# PIC32MK1024MCM064 register map
Vendor: Microchip
Registers are 32-bit, read-write, reset 0x0 unless marked. A register's access mark holds for its fields unless they carry their own. Addresses are absolute, and some are shared; only a register's first bit layout is shown; [hi:lo] are bit positions; {n}, {i} and the like mark numbered series.

## PORTD
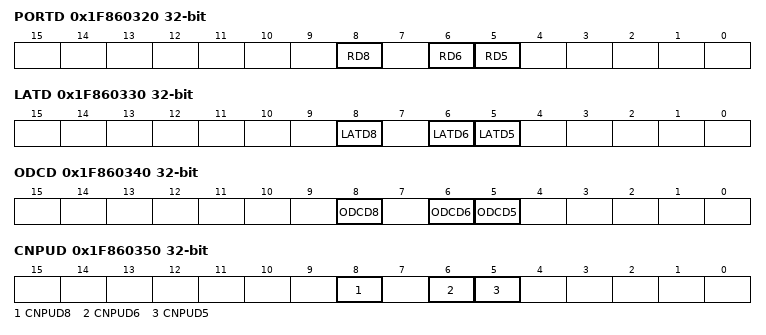
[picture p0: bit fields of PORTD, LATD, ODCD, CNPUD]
0x1F860320 PORTD reset not defined — (power-on value -----------------------x-xx-----)
  [8] RD8, [6] RD6, [5] RD5
0x1F860330 LATD reset not defined — (power-on value -----------------------x-xx-----)
  [8] LATD8, [6] LATD6, [5] LATD5
0x1F860340 ODCD
  [8] ODCD8, [6] ODCD6, [5] ODCD5
0x1F860350 CNPUD
  [8] CNPUD8, [6] CNPUD6, [5] CNPUD5
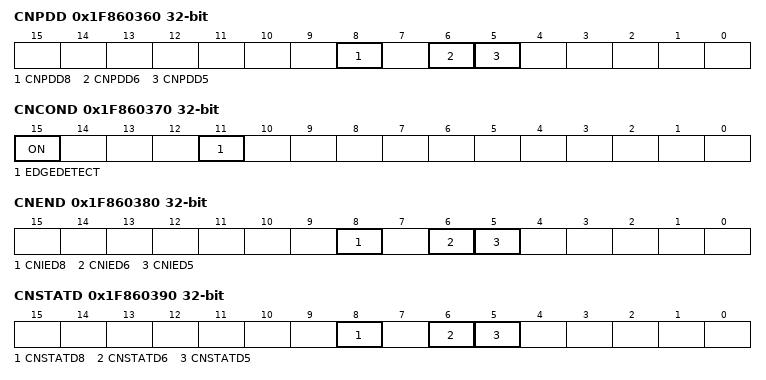
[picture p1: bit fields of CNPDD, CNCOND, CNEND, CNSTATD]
0x1F860360 CNPDD
  [8] CNPDD8, [6] CNPDD6, [5] CNPDD5
0x1F860370 CNCOND
  [15] ON, [11] EDGEDETECT
0x1F860380 CNEND
  [8] CNIED8, [6] CNIED6, [5] CNIED5
0x1F860390 CNSTATD
  [8] CNSTATD8, [6] CNSTATD6, [5] CNSTATD5
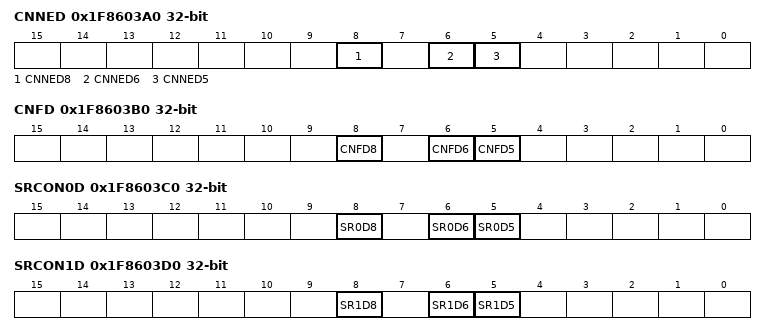
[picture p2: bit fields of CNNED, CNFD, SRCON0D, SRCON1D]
0x1F8603A0 CNNED
  [8] CNNED8, [6] CNNED6, [5] CNNED5
0x1F8603B0 CNFD
  [8] CNFD8, [6] CNFD6, [5] CNFD5
0x1F8603C0 SRCON0D
  [8] SR0D8, [6] SR0D6, [5] SR0D5
0x1F8603D0 SRCON1D
  [8] SR1D8, [6] SR1D6, [5] SR1D5

## PORTE
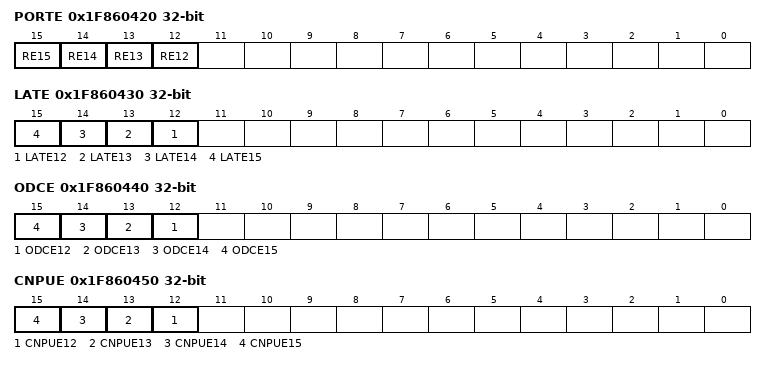
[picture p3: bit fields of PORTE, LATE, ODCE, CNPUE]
0x1F860420 PORTE reset not defined — (power-on value ----------------xxxx------------)
  [n] RE{n} (n=12..15)
0x1F860430 LATE reset not defined — (power-on value ----------------xxxx------------)
  [n] LATE{n} (n=12..15)
0x1F860440 ODCE
  [n] ODCE{n} (n=12..15)
0x1F860450 CNPUE
  [n] CNPUE{n} (n=12..15)
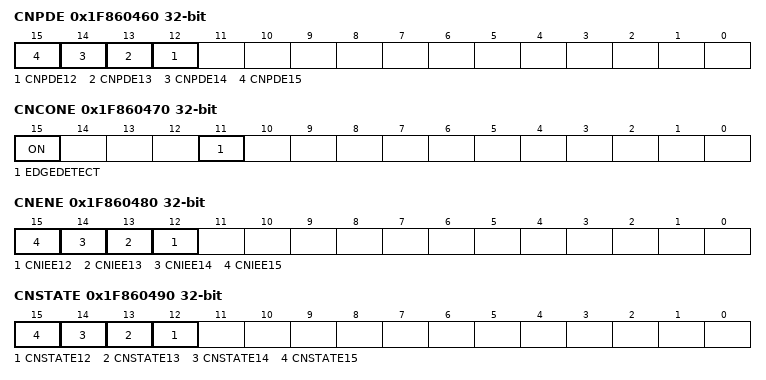
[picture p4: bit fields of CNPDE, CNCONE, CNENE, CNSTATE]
0x1F860460 CNPDE
  [n] CNPDE{n} (n=12..15)
0x1F860470 CNCONE
  [15] ON, [11] EDGEDETECT
0x1F860480 CNENE
  [n] CNIEE{n} (n=12..15)
0x1F860490 CNSTATE
  [n] CNSTATE{n} (n=12..15)
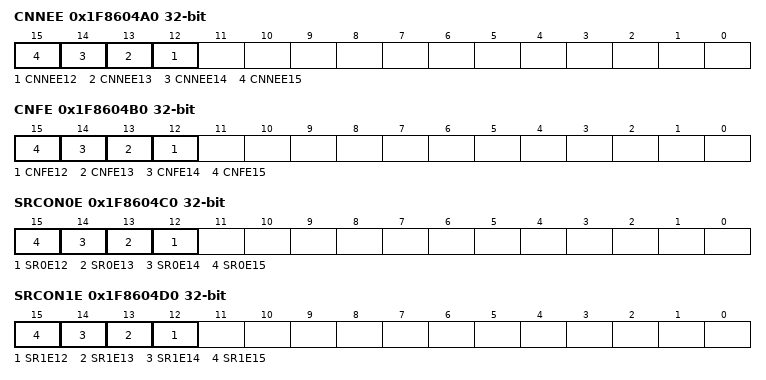
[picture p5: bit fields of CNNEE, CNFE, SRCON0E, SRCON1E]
0x1F8604A0 CNNEE
  [n] CNNEE{n} (n=12..15)
0x1F8604B0 CNFE
  [n] CNFE{n} (n=12..15)
0x1F8604C0 SRCON0E
  [n] SR0E{n} (n=12..15)
0x1F8604D0 SRCON1E
  [n] SR1E{n} (n=12..15)

## PORTF
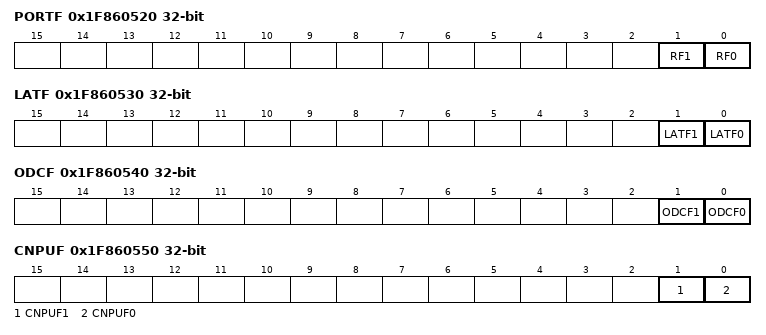
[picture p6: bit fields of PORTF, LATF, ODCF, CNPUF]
0x1F860520 PORTF reset not defined — (power-on value ------------------------------xx)
  [1] RF1, [0] RF0
0x1F860530 LATF reset not defined — (power-on value ------------------------------xx)
  [1] LATF1, [0] LATF0
0x1F860540 ODCF
  [1] ODCF1, [0] ODCF0
0x1F860550 CNPUF
  [1] CNPUF1, [0] CNPUF0
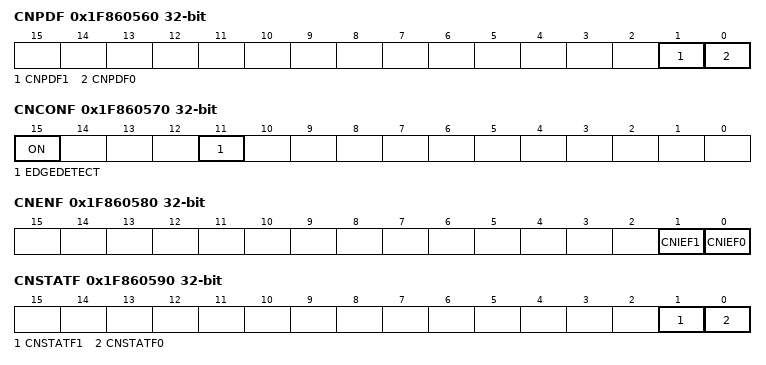
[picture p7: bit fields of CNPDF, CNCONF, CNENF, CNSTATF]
0x1F860560 CNPDF
  [1] CNPDF1, [0] CNPDF0
0x1F860570 CNCONF
  [15] ON, [11] EDGEDETECT
0x1F860580 CNENF
  [1] CNIEF1, [0] CNIEF0
0x1F860590 CNSTATF
  [1] CNSTATF1, [0] CNSTATF0
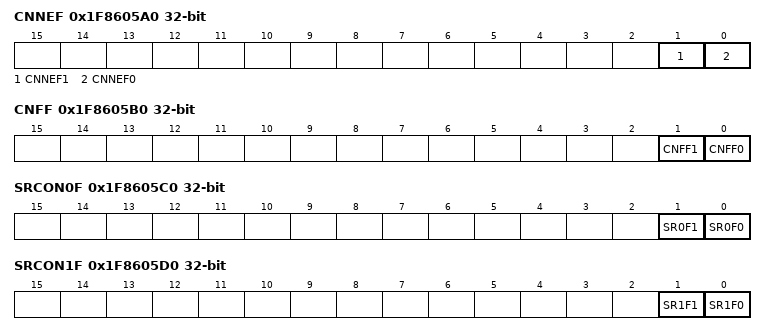
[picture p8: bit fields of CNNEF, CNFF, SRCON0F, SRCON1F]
0x1F8605A0 CNNEF
  [1] CNNEF1, [0] CNNEF0
0x1F8605B0 CNFF
  [1] CNFF1, [0] CNFF0
0x1F8605C0 SRCON0F
  [1] SR0F1, [0] SR0F0
0x1F8605D0 SRCON1F
  [1] SR1F1, [0] SR1F0

## PORTG
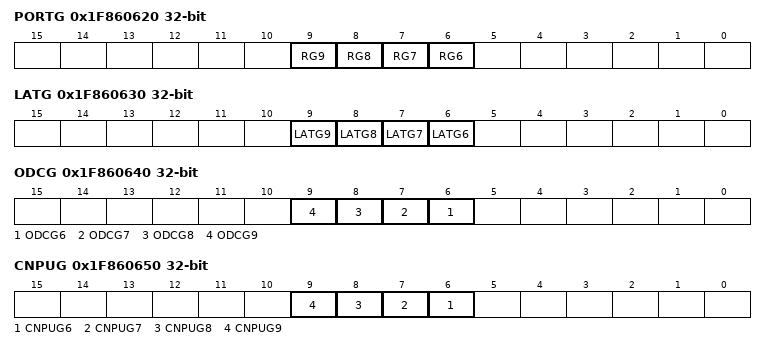
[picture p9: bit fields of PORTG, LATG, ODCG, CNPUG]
0x1F860620 PORTG reset not defined — (power-on value ----------------------xxxx------)
  [n] RG{n} (n=6..9)
0x1F860630 LATG reset not defined — (power-on value ----------------------xxxx------)
  [n] LATG{n} (n=6..9)
0x1F860640 ODCG
  [n] ODCG{n} (n=6..9)
0x1F860650 CNPUG
  [n] CNPUG{n} (n=6..9)
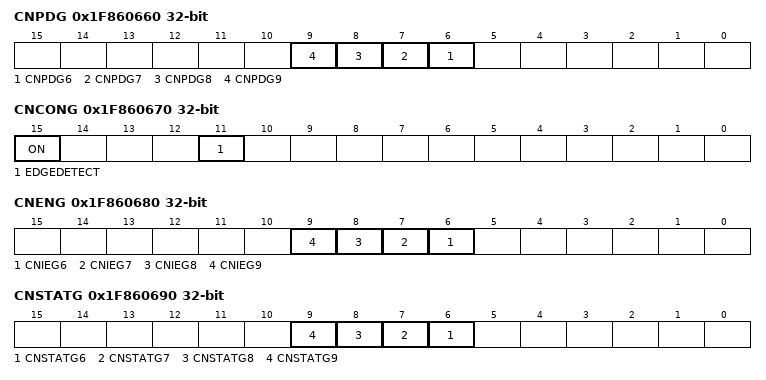
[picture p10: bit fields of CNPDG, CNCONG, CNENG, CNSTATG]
0x1F860660 CNPDG
  [n] CNPDG{n} (n=6..9)
0x1F860670 CNCONG
  [15] ON, [11] EDGEDETECT
0x1F860680 CNENG
  [n] CNIEG{n} (n=6..9)
0x1F860690 CNSTATG
  [n] CNSTATG{n} (n=6..9)
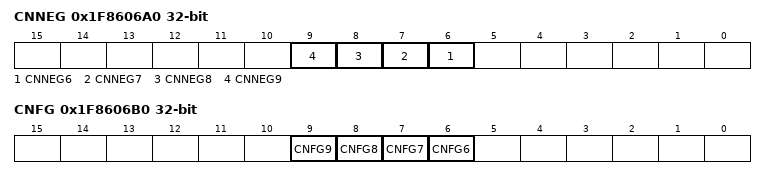
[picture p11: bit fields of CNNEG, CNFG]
0x1F8606A0 CNNEG
  [n] CNNEG{n} (n=6..9)
0x1F8606B0 CNFG
  [n] CNFG{n} (n=6..9)

## ADCHS
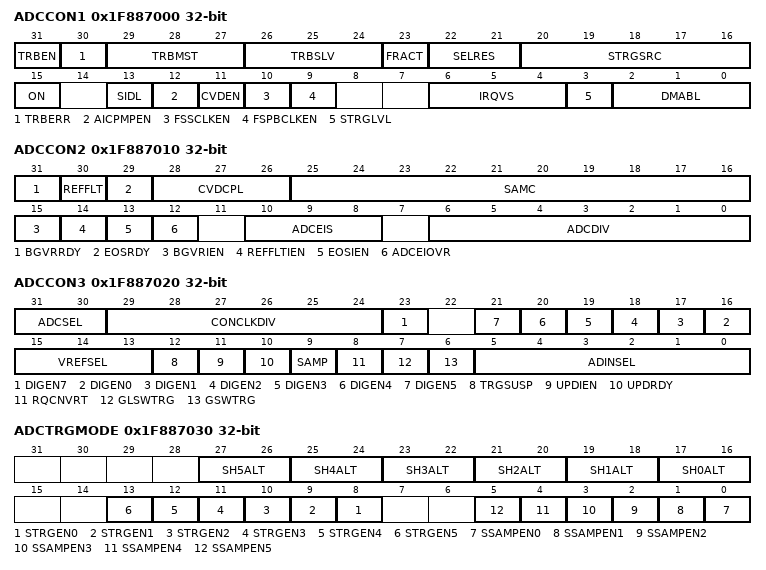
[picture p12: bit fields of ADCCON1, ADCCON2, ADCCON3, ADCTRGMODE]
0x1F887000 ADCCON1 reset not defined — (power-on value 00000110000000000-00000--0000xxx)
  [31] TRBEN, [30] TRBERR ro, [29:27] TRBMST, [26:24] TRBSLV, [23] FRACT, [22:21] SELRES, [20:16] STRGSRC, [15] ON, [13] SIDL, [12] AICPMPEN, [11] CVDEN, [10] FSSCLKEN, [9] FSPBCLKEN, [6:4] IRQVS, [3] STRGLVL, [2:0] DMABL
0x1F887010 ADCCON2
  [31] BGVRRDY ro, [30] REFFLT ro, [29] EOSRDY ro, [28:26] CVDCPL, [25:16] SAMC, [15] BGVRIEN, [14] REFFLTIEN, [13] EOSIEN, [12] ADCEIOVR, [10:8] ADCEIS, [6:0] ADCDIV
0x1F887020 ADCCON3
  [31:30] ADCSEL, [29:24] CONCLKDIV, [23] DIGEN7 ro, [n+16] DIGEN{n} ro (n=0..5), [15:13] VREFSEL, [12] TRGSUSP, [11] UPDIEN, [10] UPDRDY, [9] SAMP, [8] RQCNVRT, [7] GLSWTRG, [6] GSWTRG, [5:0] ADINSEL
0x1F887030 ADCTRGMODE
  [2n+17:2n+16] SH{n}ALT (n=0..5), [n+8] STRGEN{n} (n=0..5), [n] SSAMPEN{n} (n=0..5)
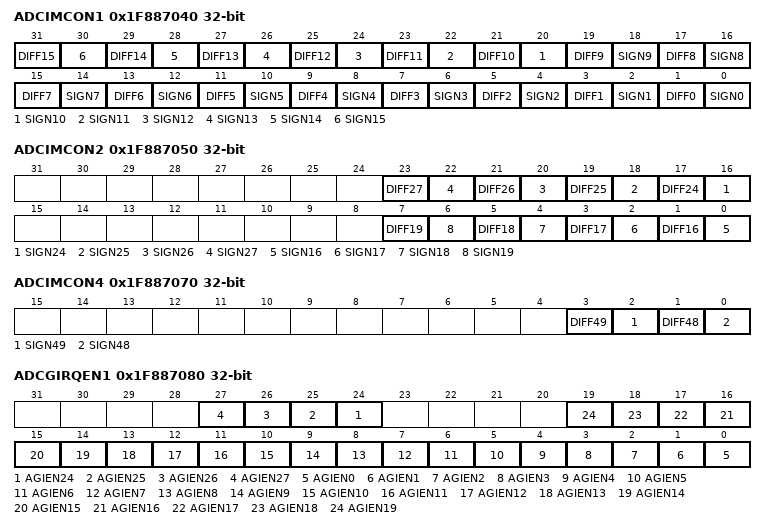
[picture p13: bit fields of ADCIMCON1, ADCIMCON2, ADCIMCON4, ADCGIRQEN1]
0x1F887040 ADCIMCON1
  [2n+1] DIFF{n} (n=0..15), [2n] SIGN{n} (n=0..15)
0x1F887050 ADCIMCON2
  [2n-31] DIFF{n} (n=24..27), [2n-32] SIGN{n} (n=24..27), [2n-31] DIFF{n} (n=16..19), [2n-32] SIGN{n} (n=16..19)
0x1F887060 ADCIMCON3 access not given reset not defined
0x1F887070 ADCIMCON4
  [3] DIFF49, [2] SIGN49, [1] DIFF48, [0] SIGN48
0x1F887080 ADCGIRQEN1
  [n] AGIEN{n} (n=24..27), [n] AGIEN{n} (n=0..19)
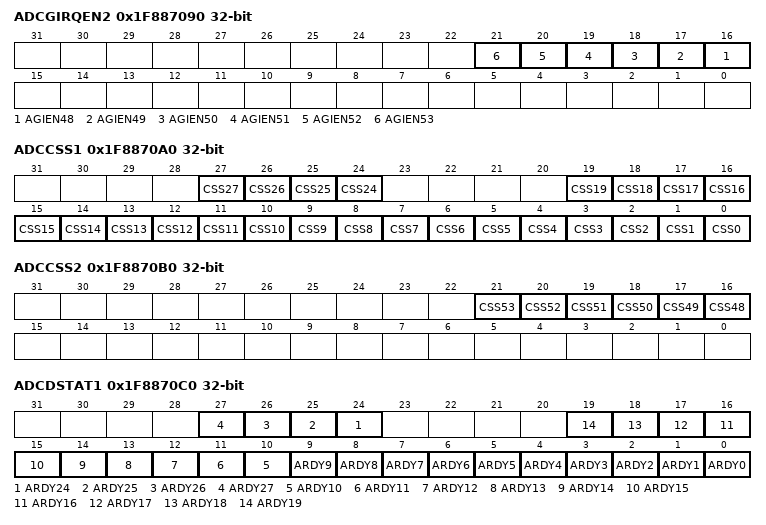
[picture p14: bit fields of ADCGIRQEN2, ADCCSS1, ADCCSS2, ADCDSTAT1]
0x1F887090 ADCGIRQEN2
  [n-32] AGIEN{n} (n=48..53)
0x1F8870A0 ADCCSS1
  [n] CSS{n} (n=24..27), [n] CSS{n} (n=0..19)
0x1F8870B0 ADCCSS2
  [n-32] CSS{n} (n=48..53)
0x1F8870C0 ADCDSTAT1 ro
  [n] ARDY{n} (n=24..27), [n] ARDY{n} (n=0..19)
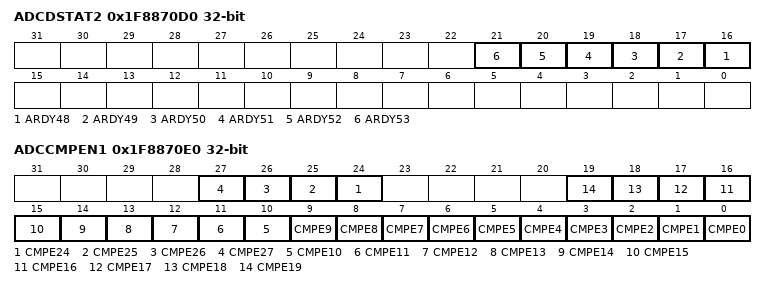
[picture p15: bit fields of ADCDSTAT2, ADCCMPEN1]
0x1F8870D0 ADCDSTAT2 ro
  [n-32] ARDY{n} (n=48..53)
0x1F8870E0 ADCCMPEN1
  [n] CMPE{n} (n=24..27), [n] CMPE{n} (n=0..19)
0x1F8870F0 ADCCMP1
  [31:16] DCMPHI, [15:0] DCMPLO
0x1F8871A0 ADCFLTR1
  [31] AFEN, [30] DATA16EN, [29] DFMODE, [28:26] OVRSAM, [25] AFGIEN, [24] AFRDY ro, [20:16] CHNLID, [15:0] FLTRDATA ro
0x1F887200 ADCTRG1
  [8n+4:8n] TRGSRC{n} (n=0..3)
0x1F887210 ADCTRG2
  [8n-28:8n-32] TRGSRC{n} (n=4..7)
0x1F887220 ADCTRG3
  [8n-60:8n-64] TRGSRC{n} (n=8..11)
0x1F887230 ADCTRG4
  [8n-92:8n-96] TRGSRC{n} (n=12..15)
0x1F887240 ADCTRG5
  [8n-124:8n-128] TRGSRC{n} (n=16..19)
0x1F887250 ADCTRG6
  [8n-156:8n-160] TRGSRC{n} (n=20..23)
0x1F887260 ADCTRG7
  [8n-188:8n-192] TRGSRC{n} (n=24..27)
0x1F887280 ADCCMPCON1
  [31:16] CVDDATA ro, [13:8] AINID ro, [7] ENDCMP, [6] DCMPGIEN, [5] DCMPED ro, [4] IEBTWN, [3] IEHIHI, [2] IEHILO, [1] IELOHI, [0] IELOLO
0x1F887300 ADCBASE
  [15:0] ADCBASE
0x1F887310 ADCDSTAT
  [31] DMAEN, [n+24] RBFIEN{n} (n=0..5), [23] WOVERR ro, [n+16] RBF{n} ro (n=0..5), [15] DMACEN, [n+8] RAFIEN{n} (n=0..5), [n] RAF{n} ro (n=0..5)
0x1F887320 ADCCNTB
0x1F887330 ADCDMAB
0x1F887340 ADCTRGSNS
  [n] LVL{n} (n=24..27), [n] LVL{n} (n=0..19)
0x1F887360 ADC1TIME reset not defined — (power-on value ---00000x0000000------0000000000)
  [28:26] ADCEIS, [25:24] SELRES, [23] BCHEN, [22:16] ADCDIV, [9:0] SAMC
0x1F8873C0 ADCEIEN1
  [n] EIEN{n} (n=24..27), [n] EIEN{n} (n=0..19)
0x1F8873D0 ADCEIEN2
  [n-32] EIEN{n} (n=48..53)
0x1F8873E0 ADCEISTAT1 ro
  [n] EIRDY{n} (n=24..27), [n] EIRDY{n} (n=0..19)
0x1F8873F0 ADCEISTAT2 reset not defined — (power-on value ----------xxxxxx----------------)
  [n-32] EIRDY{n} (n=48..53)
0x1F887400 ADCANCON reset not defined — (power-on value ----00000-x000000-0000000-000000)
  [27:24] WKUPCLKCNT, [23] WKIEN7, [n+16] WKIEN{n} (n=0..5), [15] WKRDY7 ro, [n+8] WKRDY{n} ro (n=0..5), [7] ANEN7, [n] ANEN{n} (n=0..5)
{0x1F887600+0x10*i} ADCDATA{i} (i=0..19)
  [31:0] DATA
{0x1F887600+0x10*i} ADCDATA{i} (i=24..27)
  [31:0] DATA
{0x1F887600+0x10*i} ADCDATA{i} (i=48..53)
  [31:0] DATA
{0x1F887D00+0x10*i} ADC{i}CFG (i=0..7)
  [31:0] ADCCFG
0x1F887E00 ADCSYSCFG0 ro
  [n] AN{n} (n=24..27), [n] AN{n} (n=0..19)
0x1F887E10 ADCSYSCFG1 ro
  [n-32] AN{n} (n=48..53)
